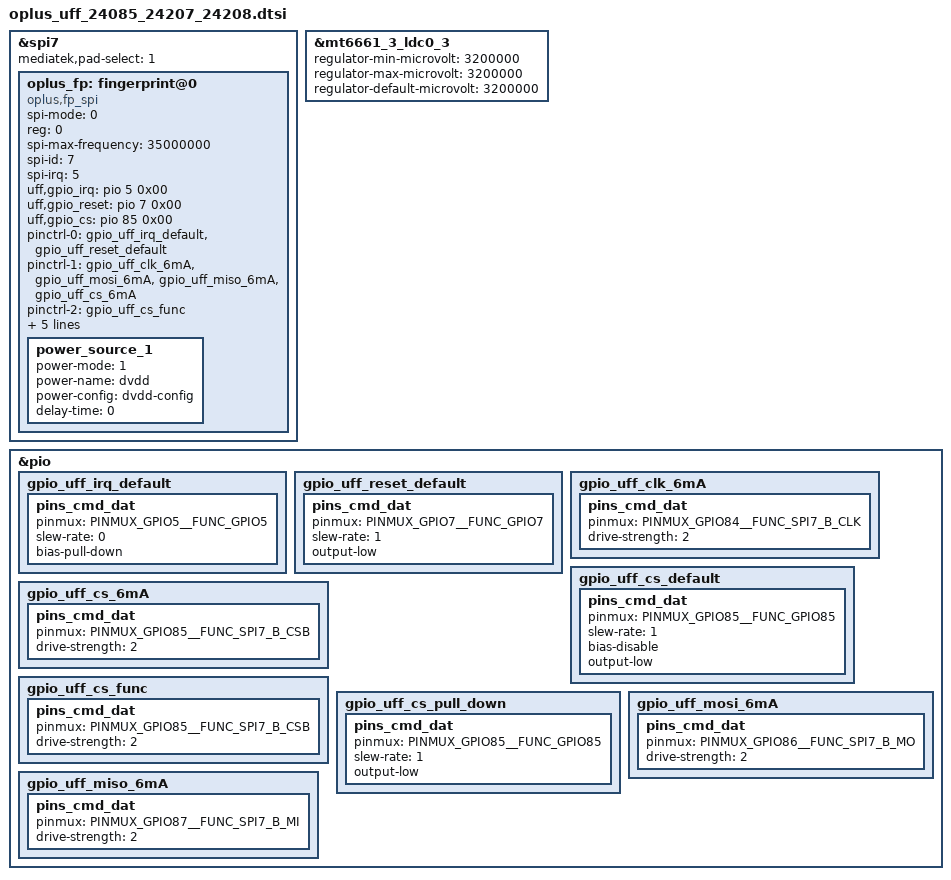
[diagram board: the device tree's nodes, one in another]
// SPDX-License-Identifier: GPL-2.0-only
/*
* Copyright (C) 2021-2025 Oplus. All rights reserved.
*/
#include <dt-bindings/iio/mt635x-auxadc.h>
#include <dt-bindings/pinctrl/mt6993-pinfunc.h>
#include <dt-bindings/pinctrl/mt65xx.h>

/* UFF dts config at 2025.02.06
 *
 * fp vendor:
 *   goodix
 */

/* FINGERPRINT start */
&spi7 {
#address-cells = <1>;
#size-cells = <0>;
status = "okay";
mediatek,pad-select = <1>;
oplus_fp: fingerprint@0 {
		compatible = "oplus,fp_spi";
		spi-mode = <0>;
		reg = <0>;
		spi-max-frequency = <35000000>;
		spi-id = <7>;
		spi-irq = <5>;
		// spi-reg = <161f0000>;
		uff,gpio_irq = <&pio 5 0x00>;
		uff,gpio_reset = <&pio 7 0x00>;
		uff,gpio_cs = <&pio 85 0x00>;
		pinctrl-names = "default", "fp_spi_driver", "fp_cs_func", "gpio_cs_pull_down";
		pinctrl-0 = <&gpio_uff_irq_default>, <&gpio_uff_reset_default>;
		pinctrl-1 = <&gpio_uff_clk_6mA>, <&gpio_uff_mosi_6mA>, <&gpio_uff_miso_6mA>, <&gpio_uff_cs_6mA>;
		pinctrl-2 = <&gpio_uff_cs_func>;
		pinctrl-3 = <&gpio_uff_cs_pull_down>;
		dvdd-supply = <&mt6661_3_ldc0_3>;
		dvdd-config = <3200000 3200000 120000>;
		optical_irq_disable_flag = <0>;
		power-num = <1>;
		status = "okay";
		power_source_1 {
			power-mode = <1>;
			power-name = "dvdd";
			power-config = "dvdd-config";
			delay-time = <0>;
		};
	};
};

&mt6661_3_ldc0_3 {
	regulator-min-microvolt = <3200000>;
	regulator-max-microvolt = <3200000>;
	regulator-default-microvolt = <3200000>;
};

&pio{
gpio_uff_irq_default: gpio_uff_irq_default {
				pins_cmd_dat {
					pinmux = <PINMUX_GPIO5__FUNC_GPIO5>;
					slew-rate = <0>;
					bias-pull-down;
				};
			};
gpio_uff_reset_default: gpio_uff_reset_default {
				pins_cmd_dat {
					pinmux = <PINMUX_GPIO7__FUNC_GPIO7>;
					slew-rate = <1>;
					output-low;
				};
			};
gpio_uff_clk_6mA: gpio_uff_clk_6mA {
				pins_cmd_dat {
					pinmux = <PINMUX_GPIO84__FUNC_SPI7_B_CLK>;
					drive-strength = <2>;
				};
			};
gpio_uff_cs_default: gpio_uff_cs_default {
				pins_cmd_dat {
					pinmux = <PINMUX_GPIO85__FUNC_GPIO85>;
					slew-rate = <1>;
					bias-disable;
					output-low;
				};
			};
gpio_uff_cs_6mA: gpio_uff_cs_6mA {
				pins_cmd_dat {
					pinmux = <PINMUX_GPIO85__FUNC_SPI7_B_CSB>;
					drive-strength = <2>;
				};
			};
gpio_uff_cs_func: gpio_uff_cs_func {
					pins_cmd_dat {
					pinmux = <PINMUX_GPIO85__FUNC_SPI7_B_CSB>;
					drive-strength = <2>;
				};
			};
gpio_uff_cs_pull_down:gpio_uff_cs_pull_down{
					pins_cmd_dat{
					pinmux = <PINMUX_GPIO85__FUNC_GPIO85>;
					slew-rate = <1>;
					output-low;
				};
			};
gpio_uff_mosi_6mA: gpio_uff_mosi_6mA {
				pins_cmd_dat {
					pinmux = <PINMUX_GPIO86__FUNC_SPI7_B_MO>;
					drive-strength = <2>;
				};
			};
gpio_uff_miso_6mA: gpio_uff_miso_6mA {
				pins_cmd_dat {
					pinmux = <PINMUX_GPIO87__FUNC_SPI7_B_MI>;
					drive-strength = <2>;
				};
			};
};
/* FINGERPRINT end */
